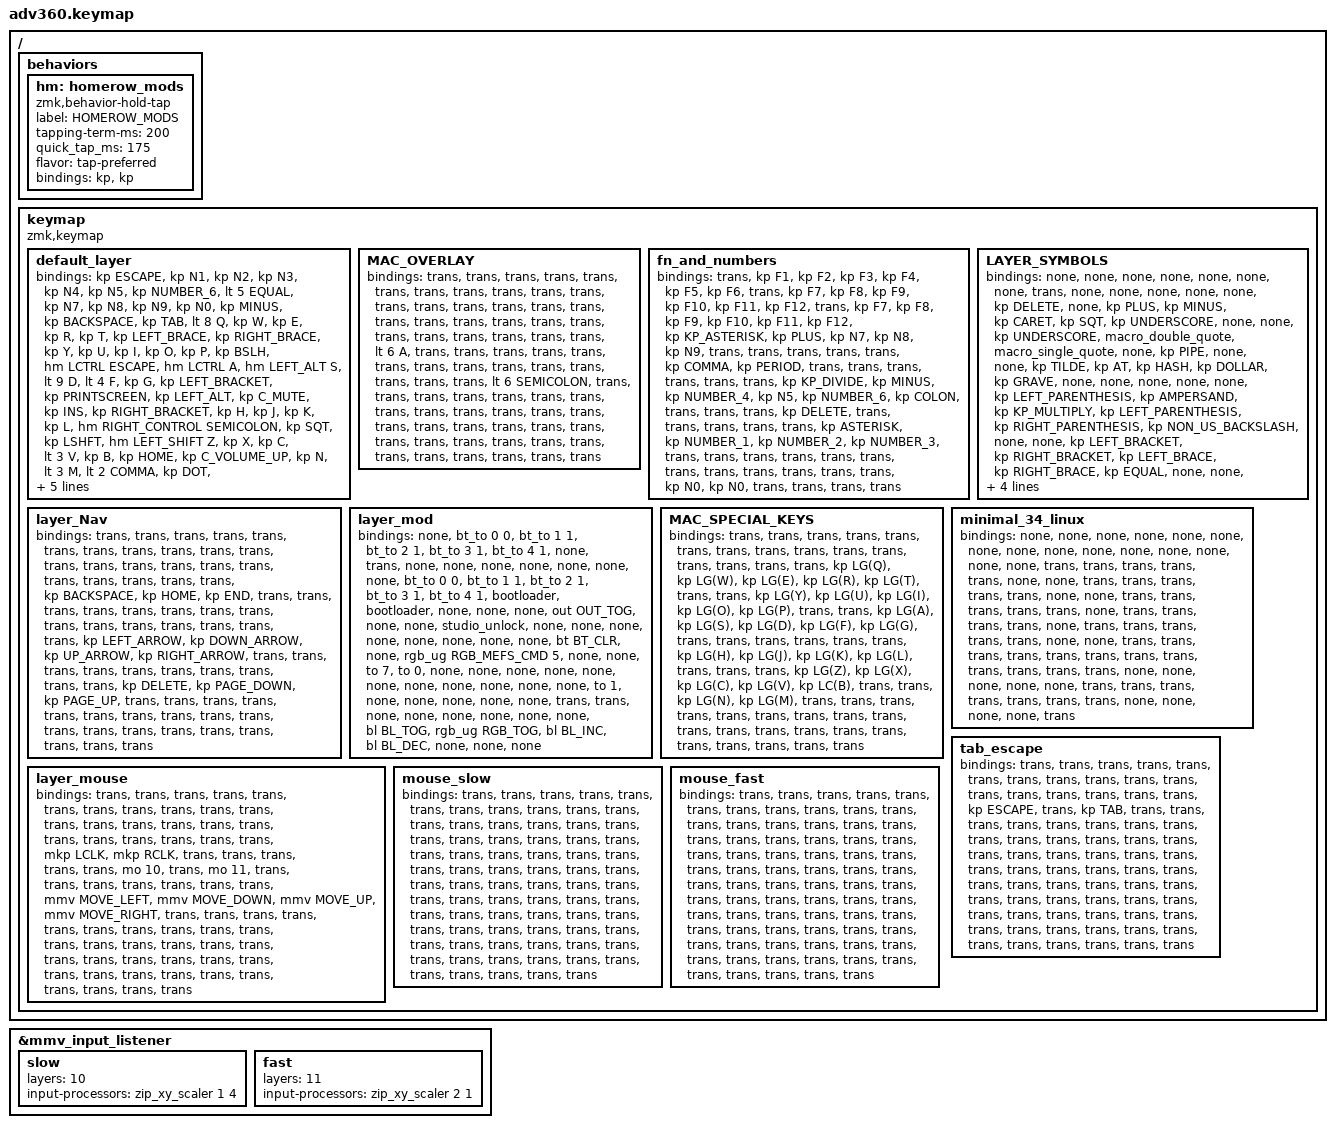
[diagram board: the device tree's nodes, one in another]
/*
 * Copyright (c) 2020 The ZMK Contributors
 *
 * SPDX-License-Identifier: MIT
 */
/* THIS FILE WAS GENERATED!
 *
 * This file was generated automatically. You may or may not want to
 * edit it directly.
 */

#include <dt-bindings/zmk/stp.h>
#include <behaviors.dtsi>
#include <input/processors.dtsi>
#include <dt-bindings/zmk/backlight.h>
#include <dt-bindings/zmk/bt.h>
#include <dt-bindings/zmk/keys.h>
#include <dt-bindings/zmk/rgb.h>
#include <dt-bindings/zmk/outputs.h>
#include <dt-bindings/zmk/pointing.h>

/ {
    behaviors {
        #include "macros.dtsi"
      #include "version.dtsi"

        hm: homerow_mods {
            compatible = "zmk,behavior-hold-tap";
            label = "HOMEROW_MODS";
            #binding-cells = <2>;
            tapping-term-ms = <200>;
            quick_tap_ms = <175>;
            flavor = "tap-preferred";
            bindings = <&kp>, <&kp>;
        };
    };

    keymap {
        compatible = "zmk,keymap";

        default_layer {
            bindings = <
&kp ESCAPE        &kp N1            &kp N2          &kp N3      &kp N4   &kp N5  &kp NUMBER_6                                                                                 &lt 5 EQUAL        &kp N7  &kp N8    &kp N9       &kp N0        &kp MINUS                    &kp BACKSPACE
&kp TAB           &lt 8 Q           &kp W           &kp E       &kp R    &kp T   &kp LEFT_BRACE                                                                               &kp RIGHT_BRACE    &kp Y   &kp U     &kp I        &kp O         &kp P                        &kp BSLH
&hm LCTRL ESCAPE  &hm LCTRL A       &hm LEFT_ALT S  &lt 9 D     &lt 4 F  &kp G   &kp LEFT_BRACKET  &kp PRINTSCREEN   &kp LEFT_ALT      &kp C_MUTE         &kp INS             &kp RIGHT_BRACKET  &kp H   &kp J     &kp K        &kp L         &hm RIGHT_CONTROL SEMICOLON  &kp SQT
&kp LSHFT         &hm LEFT_SHIFT Z  &kp X           &kp C       &lt 3 V  &kp B                                       &kp HOME          &kp C_VOLUME_UP                                           &kp N   &lt 3 M   &lt 2 COMMA  &kp DOT       &hm RIGHT_SHIFT SLASH        &kp RSHFT
&kp LCTRL         &kp SPACE         &none           &none       &mo 5            &lt 2 SPACE       &hm LEFT_GUI RET  &kp END           &kp C_VOLUME_DOWN  &hm LEFT_GUI ENTER  &lt 2 SPACE                &kp LEFT  &kp DOWN     &kp UP_ARROW  &kp RIGHT                    &mo 5
            >;
        };

        MAC_OVERLAY {
            bindings = <
&trans  &trans   &trans  &trans  &trans  &trans  &trans                                      &trans  &trans  &trans  &trans  &trans  &trans           &trans
&trans  &trans   &trans  &trans  &trans  &trans  &trans                                      &trans  &trans  &trans  &trans  &trans  &trans           &trans
&trans  &lt 6 A  &trans  &trans  &trans  &trans  &trans  &trans  &trans      &trans  &trans  &trans  &trans  &trans  &trans  &trans  &lt 6 SEMICOLON  &trans
&trans  &trans   &trans  &trans  &trans  &trans                  &trans      &trans                  &trans  &trans  &trans  &trans  &trans           &trans
&trans  &trans   &trans  &trans  &trans          &trans  &trans  &trans      &trans  &trans  &trans          &trans  &trans  &trans  &trans           &trans
            >;
        };

        fn_and_numbers {
            bindings = <
&trans  &kp F1  &kp F2      &kp F3     &kp F4      &kp F5   &kp F6                                       &trans           &kp F7        &kp F8        &kp F9        &kp F10       &kp F11    &kp F12
&trans  &kp F7  &kp F8      &kp F9     &kp F10     &kp F11  &kp F12                                      &kp KP_ASTERISK  &kp PLUS      &kp N7        &kp N8        &kp N9        &trans     &trans
&trans  &trans  &trans      &kp COMMA  &kp PERIOD  &trans   &trans   &trans  &trans      &trans  &trans  &kp KP_DIVIDE    &kp MINUS     &kp NUMBER_4  &kp N5        &kp NUMBER_6  &kp COLON  &trans
&trans  &trans  &kp DELETE  &trans     &trans      &trans                    &trans      &trans                           &kp ASTERISK  &kp NUMBER_1  &kp NUMBER_2  &kp NUMBER_3  &trans     &trans
&trans  &trans  &trans      &trans     &trans               &trans   &trans  &trans      &trans  &trans  &kp N0                         &kp N0        &trans        &trans        &trans     &trans
            >;
        };

        LAYER_SYMBOLS {
            bindings = <
&none  &none             &none              &none           &none            &none           &none                                  &trans                &none           &none                &none                 &none                  &none                 &kp DELETE
&none  &kp PLUS          &kp MINUS          &kp CARET       &kp SQT          &kp UNDERSCORE  &none                                  &none                 &kp UNDERSCORE  &macro_double_quote  &macro_single_quote   &none                  &kp PIPE              &none
&none  &kp TILDE         &kp AT             &kp HASH        &kp DOLLAR       &kp GRAVE       &none  &none  &none      &none  &none  &kp LEFT_PARENTHESIS  &kp AMPERSAND   &kp KP_MULTIPLY      &kp LEFT_PARENTHESIS  &kp RIGHT_PARENTHESIS  &kp NON_US_BACKSLASH  &none
&none  &kp LEFT_BRACKET  &kp RIGHT_BRACKET  &kp LEFT_BRACE  &kp RIGHT_BRACE  &kp EQUAL                     &none      &none                               &kp EQUAL       &kp EXCL             &kp QUESTION          &none                  &none                 &none
&none  &trans            &trans             &none           &none                            &none  &none  &none      &none  &none  &trans                                &trans               &none                 &none                  &none                 &none
            >;
        };

        layer_Nav {
            bindings = <
&trans  &trans  &trans  &trans  &trans  &trans  &trans                                      &trans  &trans          &trans          &trans        &trans           &trans  &trans
&trans  &trans  &trans  &trans  &trans  &trans  &trans                                      &trans  &kp BACKSPACE   &kp HOME        &kp END       &trans           &trans  &trans
&trans  &trans  &trans  &trans  &trans  &trans  &trans  &trans  &trans      &trans  &trans  &trans  &kp LEFT_ARROW  &kp DOWN_ARROW  &kp UP_ARROW  &kp RIGHT_ARROW  &trans  &trans
&trans  &trans  &trans  &trans  &trans  &trans                  &trans      &trans                  &kp DELETE      &kp PAGE_DOWN   &kp PAGE_UP   &trans           &trans  &trans
&trans  &trans  &trans  &trans  &trans          &trans  &trans  &trans      &trans  &trans  &trans                  &trans          &trans        &trans           &trans  &trans
            >;
        };

        layer_mod {
            bindings = <
&none           &bt_to 0 0    &bt_to 1 1    &bt_to 2 1    &bt_to 3 1    &bt_to 4 1    &none                                                  &trans                  &none  &none       &none       &none         &none  &none
&none           &bt_to 0 0    &bt_to 1 1    &bt_to 2 1    &bt_to 3 1    &bt_to 4 1    &bootloader                                            &bootloader             &none  &none       &none       &out OUT_TOG  &none  &none
&studio_unlock  &none         &none         &none         &none         &none         &none        &none  &none      &bt BT_CLR  &none       &rgb_ug RGB_MEFS_CMD 5  &none  &none       &to 7       &to 0         &none  &none
&none           &none         &none         &none         &none         &none                             &none      &none                                           &none  &to 1       &none       &none         &none  &none
&none           &trans        &trans        &none         &none                       &none        &none  &none      &none       &bl BL_TOG  &rgb_ug RGB_TOG                &bl BL_INC  &bl BL_DEC  &none         &none  &none
            >;
        };

        MAC_SPECIAL_KEYS {
            bindings = <
&trans  &trans     &trans     &trans     &trans     &trans     &trans                                      &trans  &trans     &trans     &trans     &trans     &trans     &trans
&trans  &kp LG(Q)  &kp LG(W)  &kp LG(E)  &kp LG(R)  &kp LG(T)  &trans                                      &trans  &kp LG(Y)  &kp LG(U)  &kp LG(I)  &kp LG(O)  &kp LG(P)  &trans
&trans  &kp LG(A)  &kp LG(S)  &kp LG(D)  &kp LG(F)  &kp LG(G)  &trans  &trans  &trans      &trans  &trans  &trans  &kp LG(H)  &kp LG(J)  &kp LG(K)  &kp LG(L)  &trans     &trans
&trans  &kp LG(Z)  &kp LG(X)  &kp LG(C)  &kp LG(V)  &kp LC(B)                  &trans      &trans                  &kp LG(N)  &kp LG(M)  &trans     &trans     &trans     &trans
&trans  &trans     &trans     &trans     &trans                &trans  &trans  &trans      &trans  &trans  &trans             &trans     &trans     &trans     &trans     &trans
            >;
        };

        minimal_34_linux {
            bindings = <
&none  &none   &none   &none   &none   &none   &none                                       &none   &none   &none   &none   &none   &none   &none
&none  &trans  &trans  &trans  &trans  &trans  &none                                       &none   &trans  &trans  &trans  &trans  &trans  &none
&none  &trans  &trans  &trans  &trans  &trans  &none   &trans  &trans      &trans  &trans  &none   &trans  &trans  &trans  &trans  &trans  &none
&none  &trans  &trans  &trans  &trans  &trans                  &trans      &trans                  &trans  &trans  &trans  &trans  &trans  &none
&none  &none   &none   &none   &trans          &trans  &trans  &trans      &trans  &trans  &trans          &none   &none   &none   &none   &trans
            >;
        };

        tab_escape {
            bindings = <
&trans  &trans  &trans  &trans      &trans  &trans   &trans                                      &trans  &trans  &trans  &trans  &trans  &trans  &trans
&trans  &trans  &trans  &kp ESCAPE  &trans  &kp TAB  &trans                                      &trans  &trans  &trans  &trans  &trans  &trans  &trans
&trans  &trans  &trans  &trans      &trans  &trans   &trans  &trans  &trans      &trans  &trans  &trans  &trans  &trans  &trans  &trans  &trans  &trans
&trans  &trans  &trans  &trans      &trans  &trans                   &trans      &trans                  &trans  &trans  &trans  &trans  &trans  &trans
&trans  &trans  &trans  &trans      &trans           &trans  &trans  &trans      &trans  &trans  &trans          &trans  &trans  &trans  &trans  &trans
            >;
        };

        layer_mouse {
            bindings = <
&trans  &trans  &trans  &trans  &trans  &trans  &trans                                      &trans  &trans          &trans          &trans        &trans           &trans  &trans
&trans  &trans  &trans  &trans  &trans  &trans  &trans                                      &trans  &trans          &mkp LCLK       &mkp RCLK     &trans           &trans  &trans
&trans  &trans  &mo 10  &trans  &mo 11  &trans  &trans  &trans  &trans      &trans  &trans  &trans  &mmv MOVE_LEFT  &mmv MOVE_DOWN  &mmv MOVE_UP  &mmv MOVE_RIGHT  &trans  &trans
&trans  &trans  &trans  &trans  &trans  &trans                  &trans      &trans                  &trans          &trans          &trans        &trans           &trans  &trans
&trans  &trans  &trans  &trans  &trans          &trans  &trans  &trans      &trans  &trans  &trans                  &trans          &trans        &trans           &trans  &trans
            >;
        };

        mouse_slow {
            bindings = <
&trans  &trans  &trans  &trans  &trans  &trans  &trans                                      &trans  &trans          &trans          &trans        &trans           &trans  &trans
&trans  &trans  &trans  &trans  &trans  &trans  &trans                                      &trans  &trans          &trans          &trans        &trans           &trans  &trans
&trans  &trans  &trans  &trans  &trans  &trans  &trans  &trans  &trans      &trans  &trans  &trans  &trans          &trans          &trans        &trans           &trans  &trans
&trans  &trans  &trans  &trans  &trans  &trans                  &trans      &trans                  &trans          &trans          &trans        &trans           &trans  &trans
&trans  &trans  &trans  &trans  &trans          &trans  &trans  &trans      &trans  &trans  &trans                  &trans          &trans        &trans           &trans  &trans
            >;
        };

        mouse_fast {
            bindings = <
&trans  &trans  &trans  &trans  &trans  &trans  &trans                                      &trans  &trans          &trans          &trans        &trans           &trans  &trans
&trans  &trans  &trans  &trans  &trans  &trans  &trans                                      &trans  &trans          &trans          &trans        &trans           &trans  &trans
&trans  &trans  &trans  &trans  &trans  &trans  &trans  &trans  &trans      &trans  &trans  &trans  &trans          &trans          &trans        &trans           &trans  &trans
&trans  &trans  &trans  &trans  &trans  &trans                  &trans      &trans                  &trans          &trans          &trans        &trans           &trans  &trans
&trans  &trans  &trans  &trans  &trans          &trans  &trans  &trans      &trans  &trans  &trans                  &trans          &trans        &trans           &trans  &trans
            >;
        };
    };
};

// Mouse speed while holding S (mouse_slow) or F (mouse_fast) on layer_mouse.
// Scaler args are <multiplier divisor>: tune them here.
&mmv_input_listener {
    slow {
        layers = <10>;
        input-processors = <&zip_xy_scaler 1 4>;
    };

    fast {
        layers = <11>;
        input-processors = <&zip_xy_scaler 2 1>;
    };
};
